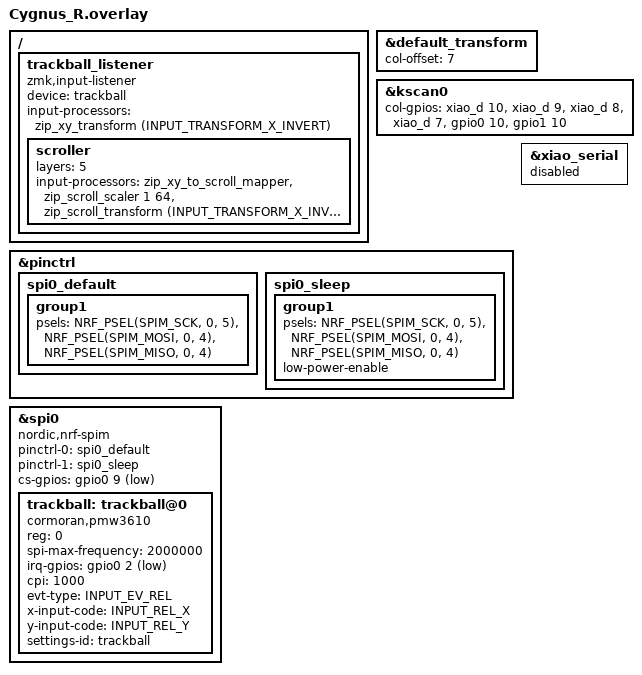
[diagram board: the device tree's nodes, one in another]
#include "Cygnus.dtsi"
#include <zephyr/dt-bindings/input/input-event-codes.h>
#include <input/processors.dtsi>
#include <dt-bindings/zmk/input_transform.h>

&default_transform {
    col-offset = <7>;
};

&kscan0 {
        col-gpios
            = <&xiao_d 10 GPIO_ACTIVE_HIGH>
            , <&xiao_d 9 GPIO_ACTIVE_HIGH>
            , <&xiao_d 8 GPIO_ACTIVE_HIGH>
            , <&xiao_d 7 GPIO_ACTIVE_HIGH>
            , <&gpio0 10 GPIO_ACTIVE_HIGH>
            , <&gpio1 10 GPIO_ACTIVE_HIGH>
            ;
};

/ {
    trackball_listener {
        compatible = "zmk,input-listener";
        device = <&trackball>;

        /* ポインタ移動の左右を反転（2026-08-13 秀星さん依頼）。
           スクロールは scroller 子ノード側が先に REL_HWHEEL へ変換するため影響しない */
        input-processors = <&zip_xy_transform (INPUT_TRANSFORM_X_INVERT)>;

        /* 旧ドライバの scroll-layers = <5> / SCROLL_TICK=64 / INVERT_SCROLL_X=y の代替:
           レイヤー5（SCROLL）では移動をスクロールへ変換し、1/64 に減速、横に加え
           縦も反転（2026-08-13 秀星さん依頼「トラックボールモードの上下も逆に」） */
        scroller {
            layers = <5>;
            input-processors
                = <&zip_xy_to_scroll_mapper>
                , <&zip_scroll_scaler 1 64>
                , <&zip_scroll_transform (INPUT_TRANSFORM_X_INVERT | INPUT_TRANSFORM_Y_INVERT)>
                ;
        };
    };
};

&pinctrl {
    spi0_default: spi0_default {
        group1 {
            psels = <NRF_PSEL(SPIM_SCK, 0, 5)>,
                <NRF_PSEL(SPIM_MOSI, 0, 4)>,
                <NRF_PSEL(SPIM_MISO, 0, 4)>;
        };
    };

    spi0_sleep: spi0_sleep {
        group1 {
            psels = <NRF_PSEL(SPIM_SCK, 0, 5)>,
                <NRF_PSEL(SPIM_MOSI, 0, 4)>,
                <NRF_PSEL(SPIM_MISO, 0, 4)>;
            low-power-enable;
        };
    };
};

&xiao_serial { status = "disabled"; };

&spi0 {
    status = "okay";
    compatible = "nordic,nrf-spim";
    pinctrl-0 = <&spi0_default>;
    pinctrl-1 = <&spi0_sleep>;
    pinctrl-names = "default", "sleep";
    cs-gpios = <&gpio0 9 GPIO_ACTIVE_LOW>;

    /* cormoran,pmw3610（DYA Studio RPC 対応ドライバ）。
       旧 pixart,pmw3610 の automouse-layer=<0>（無効値）と scroll-layers は撤去。
       CPI は旧 CONFIG_PMW3610_CPI=1000 を DTS プロパティで踏襲 */
    trackball: trackball@0 {
        status = "okay";
        compatible = "cormoran,pmw3610";
        reg = <0>;
        spi-max-frequency = <2000000>;
        irq-gpios = <&gpio0 2 (GPIO_ACTIVE_LOW | GPIO_PULL_UP)>;
        cpi = <1000>;
        evt-type = <INPUT_EV_REL>;
        x-input-code = <INPUT_REL_X>;
        y-input-code = <INPUT_REL_Y>;
        settings-id = "trackball";
    };
};
